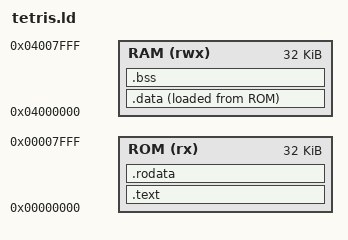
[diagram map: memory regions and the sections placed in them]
MEMORY
{
    ROM (rx)  : ORIGIN = 0x00000000, LENGTH = 32K
    RAM (rwx) : ORIGIN = 0x04000000, LENGTH = 32K
}

SECTIONS
{
    .text : {
        *(.text.start)
        *(.text*)
    } > ROM

    .rodata : {
        *(.rodata*)
    } > ROM

    .data : {
        _data_start = .;
        *(.data*)
        _data_end = .;
    } > RAM AT> ROM
    _data_load = LOADADDR(.data);

    .bss : {
        _bss_start = .;
        *(.bss*)
        *(COMMON)
        _bss_end = .;
    } > RAM
}
